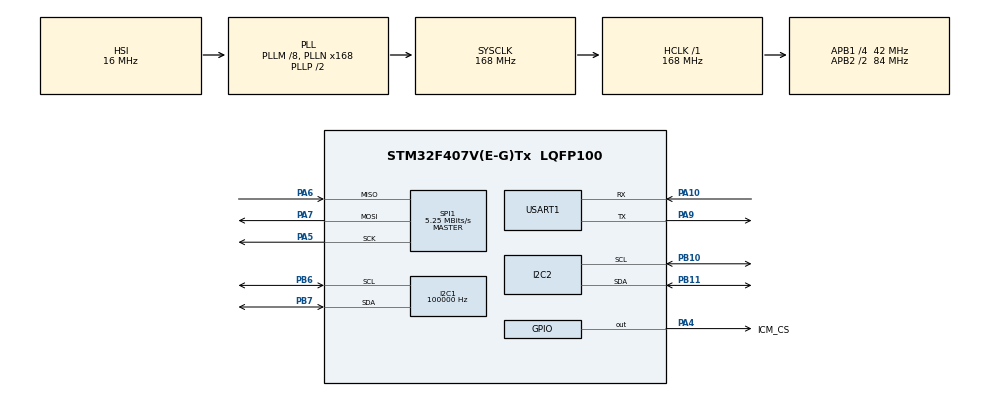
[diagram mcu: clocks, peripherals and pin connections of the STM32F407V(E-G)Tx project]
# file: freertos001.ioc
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Dma.Request0=USART1_RX
Dma.Request1=USART1_TX
Dma.USART1_RX.0.Direction=DMA_PERIPH_TO_MEMORY
Dma.USART1_RX.0.FIFOMode=DMA_FIFOMODE_DISABLE
Dma.USART1_RX.0.Instance=DMA2_Stream2
Dma.USART1_RX.0.MemDataAlignment=DMA_MDATAALIGN_BYTE
Dma.USART1_RX.0.MemInc=DMA_MINC_ENABLE
Dma.USART1_RX.0.Mode=DMA_NORMAL
Dma.USART1_RX.0.PeriphDataAlignment=DMA_PDATAALIGN_BYTE
Dma.USART1_RX.0.PeriphInc=DMA_PINC_DISABLE
Dma.USART1_RX.0.Priority=DMA_PRIORITY_LOW
Dma.USART1_TX.1.Direction=DMA_MEMORY_TO_PERIPH
Dma.USART1_TX.1.FIFOMode=DMA_FIFOMODE_DISABLE
Dma.USART1_TX.1.Instance=DMA2_Stream7
Dma.USART1_TX.1.MemDataAlignment=DMA_MDATAALIGN_BYTE
Dma.USART1_TX.1.MemInc=DMA_MINC_ENABLE
Dma.USART1_TX.1.Mode=DMA_NORMAL
Dma.USART1_TX.1.PeriphDataAlignment=DMA_PDATAALIGN_BYTE
Dma.USART1_TX.1.PeriphInc=DMA_PINC_DISABLE
Dma.USART1_TX.1.Priority=DMA_PRIORITY_LOW
FREERTOS.Queues01=AngleQ,1,Angles,0,Dynamic,NULL,NULL
FREERTOS.Tasks01=IMUTask,32,384,StartIMUTask,As weak,NULL,Dynamic,NULL,NULL;UARTDMA,40,384,StartUARTDMA,As external,NULL,Dynamic,NULL,NULL;OLEDTask,8,384,StartOLEDTask,As external,NULL,Dynamic,NULL,NULL
I2C1.ClockSpeed=100000
Mcu.Family=STM32F4
Mcu.Name=STM32F407V(E-G)Tx
Mcu.Package=LQFP100
NVIC.DMA2_Stream2_IRQn=true\:5\:0\:false\:false\:true\:true\:false\:true\:true
NVIC.DMA2_Stream7_IRQn=true\:5\:0\:false\:false\:true\:true\:false\:true\:true
NVIC.PriorityGroup=NVIC_PRIORITYGROUP_4
NVIC.TIM8_TRG_COM_TIM14_IRQn=true\:15\:0\:false\:false\:true\:false\:false\:true\:true
NVIC.TimeBase=TIM8_TRG_COM_TIM14_IRQn
NVIC.TimeBaseIP=TIM14
NVIC.USART1_IRQn=true\:5\:0\:false\:false\:true\:true\:false\:true\:true
PA10.Mode=Asynchronous
PA10.Signal=USART1_RX
PA13.Mode=Serial_Wire
PA13.Signal=SYS_JTMS-SWDIO
PA14.Mode=Serial_Wire
PA14.Signal=SYS_JTCK-SWCLK
PA4.GPIO_Label=ICM_CS
PA4.Signal=GPIO_Output
PA5.Mode=Full_Duplex_Master
PA5.Signal=SPI1_SCK
PA6.Mode=Full_Duplex_Master
PA6.Signal=SPI1_MISO
PA7.Mode=Full_Duplex_Master
PA7.Signal=SPI1_MOSI
PA9.Mode=Asynchronous
PA9.Signal=USART1_TX
PB10.Mode=I2C
PB10.Signal=I2C2_SCL
PB11.Mode=I2C
PB11.Signal=I2C2_SDA
PB6.Mode=I2C
PB6.Signal=I2C1_SCL
PB7.Mode=I2C
PB7.Signal=I2C1_SDA
ProjectManager.HeapSize=0x200
ProjectManager.StackSize=0x400
ProjectManager.TargetToolchain=MDK-ARM V5.32
RCC.48MHZClocksFreq_Value=84000000
RCC.AHBFreq_Value=168000000
RCC.APB1CLKDivider=RCC_HCLK_DIV4
RCC.APB1Freq_Value=42000000
RCC.APB1TimFreq_Value=84000000
RCC.APB2CLKDivider=RCC_HCLK_DIV2
RCC.APB2Freq_Value=84000000
RCC.APB2TimFreq_Value=168000000
RCC.CortexFreq_Value=168000000
RCC.HCLKFreq_Value=168000000
RCC.HSE_VALUE=25000000
RCC.HSI_VALUE=16000000
RCC.LSE_VALUE=32768
RCC.PLLM=8
RCC.PLLN=168
RCC.SYSCLKFreq_VALUE=168000000
RCC.SYSCLKSource=RCC_SYSCLKSOURCE_PLLCLK
RCC.VCOOutputFreq_Value=336000000
SPI1.BaudRatePrescaler=SPI_BAUDRATEPRESCALER_16
SPI1.CLKPhase=SPI_PHASE_1EDGE
SPI1.CLKPolarity=SPI_POLARITY_LOW
SPI1.CalculateBaudRate=5.25 MBits/s
SPI1.DataSize=SPI_DATASIZE_8BIT
SPI1.Direction=SPI_DIRECTION_2LINES
SPI1.Mode=SPI_MODE_MASTER
SPI1.VirtualType=VM_MASTER
USART1.VirtualMode=VM_ASYNC
VP_FREERTOS_VS_CMSIS_V2.Mode=CMSIS_V2
VP_SYS_VS_tim14.Mode=TIM14
board=custom

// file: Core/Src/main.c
/* USER CODE BEGIN Header */
/**
  ******************************************************************************
  * @file           : main.c
  * @brief          : Main program body
  ******************************************************************************
  * @attention
  *
  * Copyright (c) 2026 STMicroelectronics.
  * All rights reserved.
  *
  * This software is licensed under terms that can be found in the LICENSE file
  * in the root directory of this software component.
  * If no LICENSE file comes with this software, it is provided AS-IS.
  *
  ******************************************************************************
  */
/* USER CODE END Header */
#include "main.h"
#include "cmsis_os.h"
#include "dma.h"
#include "i2c.h"
#include "spi.h"
#include "usart.h"
#include "gpio.h"

void SystemClock_Config(void);
void MX_FREERTOS_Init(void);

int main(void)
{

  /* MCU Configuration--------------------------------------------------------*/

  /* Reset of all peripherals, Initializes the Flash interface and the Systick. */
  HAL_Init();

  /* Configure the system clock */
  SystemClock_Config();

  /* Initialize all configured peripherals */
  MX_GPIO_Init();
  MX_DMA_Init();
  MX_USART1_UART_Init();
  MX_I2C1_Init();
  MX_SPI1_Init();
  MX_I2C2_Init();

  /* Init scheduler */
  osKernelInitialize();  /* Call init function for freertos objects (in cmsis_os2.c) */
  MX_FREERTOS_Init();

  /* Start scheduler */
  osKernelStart();

  /* We should never get here as control is now taken by the scheduler */

  /* Infinite loop */
  while (1)
  {

  }
}

void SystemClock_Config(void)
{
  RCC_OscInitTypeDef RCC_OscInitStruct = {0};
  RCC_ClkInitTypeDef RCC_ClkInitStruct = {0};

  /** Configure the main internal regulator output voltage
  */
  __HAL_RCC_PWR_CLK_ENABLE();
  __HAL_PWR_VOLTAGESCALING_CONFIG(PWR_REGULATOR_VOLTAGE_SCALE1);

  /** Initializes the RCC Oscillators according to the specified parameters
  * in the RCC_OscInitTypeDef structure.
  */
  RCC_OscInitStruct.OscillatorType = RCC_OSCILLATORTYPE_HSI;
  RCC_OscInitStruct.HSIState = RCC_HSI_ON;
  RCC_OscInitStruct.HSICalibrationValue = RCC_HSICALIBRATION_DEFAULT;
  RCC_OscInitStruct.PLL.PLLState = RCC_PLL_ON;
  RCC_OscInitStruct.PLL.PLLSource = RCC_PLLSOURCE_HSI;
  RCC_OscInitStruct.PLL.PLLM = 8;
  RCC_OscInitStruct.PLL.PLLN = 168;
  RCC_OscInitStruct.PLL.PLLP = RCC_PLLP_DIV2;
  RCC_OscInitStruct.PLL.PLLQ = 4;
  if (HAL_RCC_OscConfig(&RCC_OscInitStruct) != HAL_OK)
  {
    Error_Handler();
  }

  /** Initializes the CPU, AHB and APB buses clocks
  */
  RCC_ClkInitStruct.ClockType = RCC_CLOCKTYPE_HCLK|RCC_CLOCKTYPE_SYSCLK
                              |RCC_CLOCKTYPE_PCLK1|RCC_CLOCKTYPE_PCLK2;
  RCC_ClkInitStruct.SYSCLKSource = RCC_SYSCLKSOURCE_PLLCLK;
  RCC_ClkInitStruct.AHBCLKDivider = RCC_SYSCLK_DIV1;
  RCC_ClkInitStruct.APB1CLKDivider = RCC_HCLK_DIV4;
  RCC_ClkInitStruct.APB2CLKDivider = RCC_HCLK_DIV2;

  if (HAL_RCC_ClockConfig(&RCC_ClkInitStruct, FLASH_LATENCY_5) != HAL_OK)
  {
    Error_Handler();
  }
}

void HAL_TIM_PeriodElapsedCallback(TIM_HandleTypeDef *htim)
{
  if (htim->Instance == TIM14)
  {
    HAL_IncTick();
  }
}

void Error_Handler(void)
{
  __disable_irq();
  while (1)
  {
  }
}

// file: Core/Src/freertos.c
/**
 * @file freertos.c
 * @brief FreeRTOS 任务和队列配置
 */

#include "FreeRTOS.h"
#include "task.h"
#include "main.h"
#include "cmsis_os.h"

/* USER CODE BEGIN Includes */
#include "app.h"
#include "app_uart.h"
#include "app_imu.h"
#include "app_oled.h"
/* USER CODE END Includes */

/* Definitions for IMUTask */
osThreadId_t IMUTaskHandle;
const osThreadAttr_t IMUTask_attributes = {
  .name = "IMUTask",
  .stack_size = 384 * 4,
  .priority = (osPriority_t) osPriorityAboveNormal,
};
/* Definitions for UARTDMA */
osThreadId_t UARTDMAHandle;
const osThreadAttr_t UARTDMA_attributes = {
  .name = "UARTDMA",
  .stack_size = 384 * 4,
  .priority = (osPriority_t) osPriorityHigh,
};
/* Definitions for OLEDTask */
osThreadId_t OLEDTaskHandle;
const osThreadAttr_t OLEDTask_attributes = {
  .name = "OLEDTask",
  .stack_size = 384 * 4,
  .priority = (osPriority_t) osPriorityLow,
};
/* Definitions for AngleQ */
osMessageQueueId_t AngleQHandle;
const osMessageQueueAttr_t AngleQ_attributes = {
  .name = "AngleQ"
};

void MX_FREERTOS_Init(void); /* (MISRA C 2004 rule 8.1) */

void MX_FREERTOS_Init(void) {

  /* Create the queue(s) */
  /* creation of AngleQ */
  AngleQHandle = osMessageQueueNew (1, sizeof(Angles), &AngleQ_attributes);

  /* Create the thread(s) */
  /* creation of IMUTask */
  IMUTaskHandle = osThreadNew(StartIMUTask, NULL, &IMUTask_attributes);

  /* creation of UARTDMA */
  UARTDMAHandle = osThreadNew(StartUARTDMA, NULL, &UARTDMA_attributes);

  /* creation of OLEDTask */
  OLEDTaskHandle = osThreadNew(StartOLEDTask, NULL, &OLEDTask_attributes);

}

/* USER CODE BEGIN Header_StartIMUTask */
/* IMU 任务弱定义，实际在 app_imu.c */
/* USER CODE END Header_StartIMUTask */
__weak void StartIMUTask(void *argument)
{
  /* USER CODE BEGIN StartIMUTask */
  /* 实际实现位于 app_imu.c，这里保留弱定义供 CubeMX 生成 */
  for(;;)
  {
    osDelay(1);
  }
  /* USER CODE END StartIMUTask */
}
